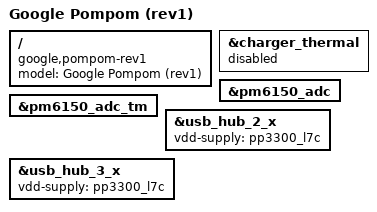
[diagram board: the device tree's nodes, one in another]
/dts-v1/;
#include "sc7180-trogdor-pompom.dtsi"
/delete-node/ &keyboard_controller;
#include <arm/cros-ec-keyboard.dtsi>
/ {
	model = "Google Pompom (rev1)";
	compatible = "google,pompom-rev1", "qcom,sc7180";
};
&charger_thermal {
	status = "disabled";
};
&pm6150_adc {
	/delete-node/ channel@4f;
};
&pm6150_adc_tm {
	/delete-node/ charger-thermistor@0;
};
&usb_hub_2_x {
	 vdd-supply = <&pp3300_l7c>;
};
&usb_hub_3_x {
	 vdd-supply = <&pp3300_l7c>;
};
